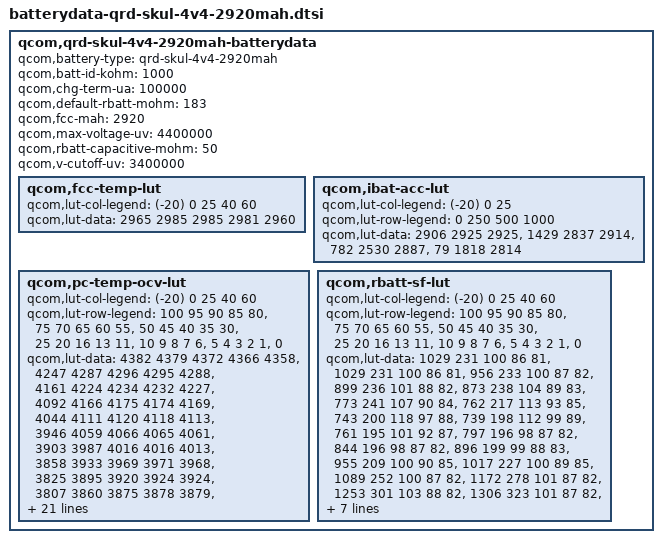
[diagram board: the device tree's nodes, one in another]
/* Copyright (c) 2015, The Linux Foundation. All rights reserved.
 *
 * This program is free software; you can redistribute it and/or modify
 * it under the terms of the GNU General Public License version 2 and
 * only version 2 as published by the Free Software Foundation.
 *
 * This program is distributed in the hope that it will be useful,
 * but WITHOUT ANY WARRANTY; without even the implied warranty of
 * MERCHANTABILITY or FITNESS FOR A PARTICULAR PURPOSE.  See the
 * GNU General Public License for more details.
 */

qcom,qrd-skul-4v4-2920mah-batterydata {
	qcom,battery-type = "qrd-skul-4v4-2920mah";
	qcom,batt-id-kohm = <1000>;
	qcom,chg-term-ua = <100000>;
	qcom,default-rbatt-mohm = <183>;
	qcom,fcc-mah = <2920>;
	qcom,max-voltage-uv = <4400000>;
	qcom,rbatt-capacitive-mohm = <50>;
	qcom,v-cutoff-uv = <3400000>;

	qcom,fcc-temp-lut {
		qcom,lut-col-legend = <(-20) 0 25 40 60>;
		qcom,lut-data = <2965 2985 2985 2981 2960>;
	};

	qcom,ibat-acc-lut {
		qcom,lut-col-legend = <(-20) 0 25>;
		qcom,lut-row-legend = <0 250 500 1000>;
		qcom,lut-data = <2906 2925 2925>,
				<1429 2837 2914>,
				<782 2530 2887>,
				<79 1818 2814>;
	};

	qcom,pc-temp-ocv-lut {
		qcom,lut-col-legend = <(-20) 0 25 40 60>;
		qcom,lut-row-legend = <100 95 90 85 80>,
					<75 70 65 60 55>,
					<50 45 40 35 30>,
					<25 20 16 13 11>,
					<10 9 8 7 6>,
					<5 4 3 2 1>,
					<0>;
		qcom,lut-data = <4382 4379 4372 4366 4358>,
				<4247 4287 4296 4295 4288>,
				<4161 4224 4234 4232 4227>,
				<4092 4166 4175 4174 4169>,
				<4044 4111 4120 4118 4113>,
				<3946 4059 4066 4065 4061>,
				<3903 3987 4016 4016 4013>,
				<3858 3933 3969 3971 3968>,
				<3825 3895 3920 3924 3924>,
				<3807 3860 3875 3878 3879>,
				<3793 3831 3842 3843 3843>,
				<3779 3806 3818 3819 3818>,
				<3764 3788 3798 3799 3798>,
				<3749 3776 3782 3783 3781>,
				<3734 3765 3769 3767 3763>,
				<3719 3749 3757 3750 3737>,
				<3702 3727 3738 3729 3716>,
				<3685 3707 3714 3707 3694>,
				<3667 3695 3690 3683 3674>,
				<3652 3689 3685 3680 3669>,
				<3642 3686 3685 3679 3668>,
				<3630 3683 3683 3677 3667>,
				<3615 3679 3681 3676 3665>,
				<3598 3673 3678 3673 3662>,
				<3578 3663 3673 3666 3652>,
				<3553 3637 3648 3640 3625>,
				<3516 3594 3601 3592 3578>,
				<3464 3532 3538 3530 3516>,
				<3382 3440 3450 3447 3432>,
				<3251 3295 3315 3325 3301>,
				<3000 3000 3000 3052 3000>;
	};

	qcom,rbatt-sf-lut {
		qcom,lut-col-legend = <(-20) 0 25 40 60>;
		qcom,lut-row-legend = <100 95 90 85 80>,
					<75 70 65 60 55>,
					<50 45 40 35 30>,
					<25 20 16 13 11>,
					<10 9 8 7 6>,
					<5 4 3 2 1>,
					<0>;
		qcom,lut-data = <1029 231 100 86 81>,
				<1029 231 100 86 81>,
				<956 233 100 87 82>,
				<899 236 101 88 82>,
				<873 238 104 89 83>,
				<773 241 107 90 84>,
				<762 217 113 93 85>,
				<743 200 118 97 88>,
				<739 198 112 99 89>,
				<761 195 101 92 87>,
				<797 196 98 87 82>,
				<844 196 98 87 82>,
				<896 199 99 88 83>,
				<955 209 100 90 85>,
				<1017 227 100 89 85>,
				<1089 252 100 87 82>,
				<1172 278 101 87 82>,
				<1253 301 103 88 82>,
				<1306 323 101 87 82>,
				<1246 323 101 88 82>,
				<1298 339 104 88 83>,
				<1351 357 105 90 84>,
				<1451 377 108 91 85>,
				<1637 402 111 93 87>,
				<1855 431 115 95 87>,
				<2128 459 115 92 85>,
				<2562 493 117 93 85>,
				<3249 556 124 96 87>,
				<4616 660 138 101 92>,
				<10855 3698 256 124 113>,
				<142404 102851 83715 2038 57906>;
	};
};
